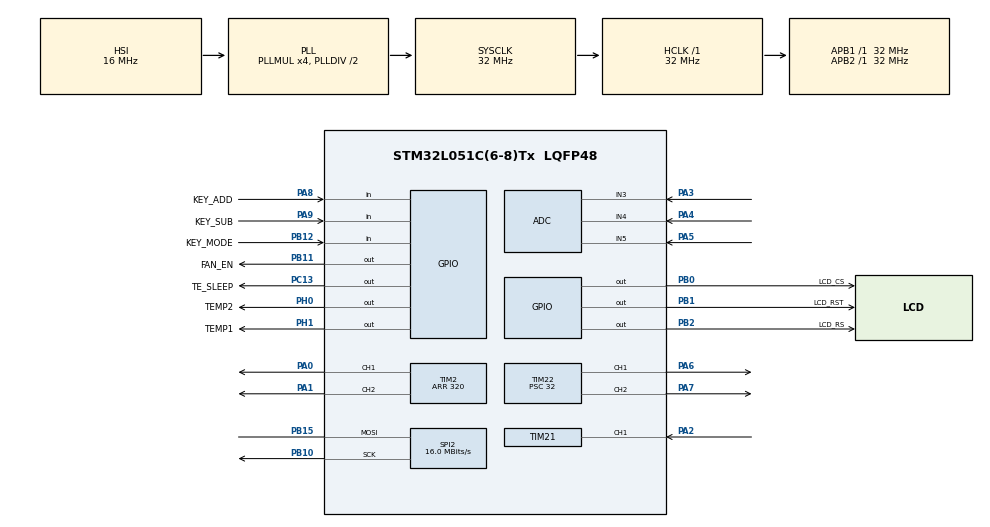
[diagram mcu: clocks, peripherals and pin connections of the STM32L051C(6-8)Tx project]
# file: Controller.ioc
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ADC.ClockPrescaler=ADC_CLOCK_ASYNC_DIV64
ADC.OversamplingMode=ENABLE
ADC.Ratio=ADC_OVERSAMPLING_RATIO_16
ADC.RightBitShift=ADC_RIGHTBITSHIFT_4
ADC.SamplingTime=ADC_SAMPLETIME_12CYCLES_5
Dma.ADC.0.Direction=DMA_PERIPH_TO_MEMORY
Dma.ADC.0.Instance=DMA1_Channel1
Dma.ADC.0.MemDataAlignment=DMA_MDATAALIGN_HALFWORD
Dma.ADC.0.MemInc=DMA_MINC_ENABLE
Dma.ADC.0.Mode=DMA_CIRCULAR
Dma.ADC.0.PeriphDataAlignment=DMA_PDATAALIGN_HALFWORD
Dma.ADC.0.PeriphInc=DMA_PINC_DISABLE
Dma.ADC.0.Priority=DMA_PRIORITY_LOW
Dma.Request0=ADC
Mcu.Family=STM32L0
Mcu.Name=STM32L051C(6-8)Tx
Mcu.Package=LQFP48
NVIC.DMA1_Channel1_IRQn=true\:2\:0\:true\:false\:true\:false\:true\:true
PA0.Signal=S_TIM2_CH1
PA1.Signal=S_TIM2_CH2
PA13.Mode=Serial_Wire
PA13.Signal=SYS_SWDIO
PA14.Mode=Serial_Wire
PA14.Signal=SYS_SWCLK
PA2.Signal=S_TIM21_CH1
PA3.Mode=IN3
PA3.Signal=ADC_IN3
PA4.Mode=IN4
PA4.Signal=ADC_IN4
PA5.Mode=IN5
PA5.Signal=ADC_IN5
PA6.Signal=S_TIM22_CH1
PA7.Signal=S_TIM22_CH2
PA8.GPIO_Label=KEY_ADD
PA8.GPIO_PuPd=GPIO_PULLUP
PA8.Signal=GPIO_Input
PA9.GPIO_Label=KEY_SUB
PA9.GPIO_PuPd=GPIO_PULLUP
PA9.Signal=GPIO_Input
PB0.GPIO_Label=LCD_CS
PB0.GPIO_Speed=GPIO_SPEED_FREQ_VERY_HIGH
PB0.Signal=GPIO_Output
PB1.GPIO_Label=LCD_RST
PB1.GPIO_Speed=GPIO_SPEED_FREQ_LOW
PB1.Signal=GPIO_Output
PB10.Mode=Simplex_Bidirectional_Master
PB10.Signal=SPI2_SCK
PB11.GPIO_Label=FAN_EN
PB11.GPIO_PuPd=GPIO_NOPULL
PB11.Signal=GPIO_Output
PB12.GPIO_Label=KEY_MODE
PB12.GPIO_PuPd=GPIO_PULLUP
PB12.Signal=GPIO_Input
PB15.Mode=Simplex_Bidirectional_Master
PB15.Signal=SPI2_MOSI
PB2.GPIO_Label=LCD_RS
PB2.GPIO_Speed=GPIO_SPEED_FREQ_VERY_HIGH
PB2.Signal=GPIO_Output
PC13.GPIO_Label=TE_SLEEP
PC13.GPIO_PuPd=GPIO_NOPULL
PC13.Signal=GPIO_Output
PH0-OSC_IN.GPIO_Label=TEMP2
PH0-OSC_IN.GPIO_ModeDefaultOutputPP=GPIO_MODE_OUTPUT_OD
PH0-OSC_IN.GPIO_PuPd=GPIO_NOPULL
PH0-OSC_IN.GPIO_Speed=GPIO_SPEED_FREQ_VERY_HIGH
PH0-OSC_IN.Signal=GPIO_Output
PH1-OSC_OUT.GPIO_Label=TEMP1
PH1-OSC_OUT.GPIO_ModeDefaultOutputPP=GPIO_MODE_OUTPUT_OD
PH1-OSC_OUT.GPIO_PuPd=GPIO_NOPULL
PH1-OSC_OUT.GPIO_Speed=GPIO_SPEED_FREQ_VERY_HIGH
PH1-OSC_OUT.Signal=GPIO_Output
ProjectManager.HeapSize=0x200
ProjectManager.StackSize=0x200
ProjectManager.TargetToolchain=STM32CubeIDE
RCC.AHBFreq_Value=32000000
RCC.APB1Freq_Value=32000000
RCC.APB1TimFreq_Value=32000000
RCC.APB2Freq_Value=32000000
RCC.APB2TimFreq_Value=32000000
RCC.HCLKFreq_Value=32000000
RCC.HSE_VALUE=8000000
RCC.HSI16_VALUE=16000000
RCC.HSI_VALUE=16000000
RCC.LSE_VALUE=32768
RCC.MSI_VALUE=2097000
RCC.PLLMUL=RCC_PLLMUL_4
RCC.SYSCLKFreq_VALUE=32000000
RCC.SYSCLKSource=RCC_SYSCLKSOURCE_PLLCLK
RCC.VCOOutputFreq_Value=64000000
SH.S_TIM21_CH1.0=TIM21_CH1,Input_Capture1_from_TI1
SH.S_TIM22_CH1.0=TIM22_CH1,PWM Generation1 CH1
SH.S_TIM22_CH2.0=TIM22_CH2,PWM Generation2 CH2
SH.S_TIM2_CH1.0=TIM2_CH1,PWM Generation1 CH1
SH.S_TIM2_CH2.0=TIM2_CH2,PWM Generation2 CH2
SPI2.BaudRatePrescaler=SPI_BAUDRATEPRESCALER_2
SPI2.CLKPolarity=SPI_POLARITY_LOW
SPI2.CalculateBaudRate=16.0 MBits/s
SPI2.Direction=SPI_DIRECTION_1LINE
SPI2.Mode=SPI_MODE_MASTER
SPI2.VirtualType=VM_MASTER
TIM2.AutoReloadPreload=TIM_AUTORELOAD_PRELOAD_ENABLE
TIM2.Channel-PWM\ Generation1\ CH1=TIM_CHANNEL_1
TIM2.Channel-PWM\ Generation2\ CH2=TIM_CHANNEL_2
TIM2.Period=320
TIM21.Channel-Input_Capture1_from_TI1=TIM_CHANNEL_1
TIM22.AutoReloadPreload=TIM_AUTORELOAD_PRELOAD_ENABLE
TIM22.Channel-PWM\ Generation1\ CH1=TIM_CHANNEL_1
TIM22.Channel-PWM\ Generation2\ CH2=TIM_CHANNEL_2
TIM22.Period=1000
TIM22.Prescaler=32
TIM6.AutoReloadPreload=TIM_AUTORELOAD_PRELOAD_ENABLE
TIM6.Period=4000
TIM6.Prescaler=32
TIM6.TIM_MasterOutputTrigger=TIM_TRGO_UPDATE
VP_ADC_TempSens_Input.Mode=IN-TempSens
VP_TIM21_VS_ClockSourceINT.Mode=Internal
VP_TIM22_VS_ClockSourceINT.Mode=Internal
VP_TIM2_VS_ClockSourceINT.Mode=Internal
VP_TIM6_VS_ClockSourceINT.Mode=Enable_Timer
board=custom

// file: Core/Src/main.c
/* USER CODE BEGIN Header */
/**
  ******************************************************************************
  * @file           : main.c
  * @brief          : Main program body
  ******************************************************************************
  * @attention
  *
  * Copyright (c) 2022 STMicroelectronics.
  * All rights reserved.
  *
  * This software is licensed under terms that can be found in the LICENSE file
  * in the root directory of this software component.
  * If no LICENSE file comes with this software, it is provided AS-IS.
  *
  ******************************************************************************
  */
/* USER CODE END Header */
#include "main.h"

/* USER CODE BEGIN Includes */

#include "userMain.hpp"

/* USER CODE END Includes */

 ADC_HandleTypeDef hadc;
DMA_HandleTypeDef hdma_adc;

SPI_HandleTypeDef hspi2;

TIM_HandleTypeDef htim2;
TIM_HandleTypeDef htim6;
TIM_HandleTypeDef htim21;
TIM_HandleTypeDef htim22;

void SystemClock_Config(void);
static void MX_GPIO_Init(void);
static void MX_ADC_Init(void);
static void MX_SPI2_Init(void);
static void MX_TIM2_Init(void);
static void MX_DMA_Init(void);
static void MX_TIM22_Init(void);
static void MX_TIM21_Init(void);
static void MX_TIM6_Init(void);

int main(void)
{

  /* MCU Configuration--------------------------------------------------------*/

  /* Reset of all peripherals, Initializes the Flash interface and the Systick. */
  HAL_Init();

  /* Configure the system clock */
  SystemClock_Config();

  /* Initialize all configured peripherals */
  MX_GPIO_Init();
  MX_ADC_Init();
  MX_SPI2_Init();
  MX_TIM2_Init();
  MX_DMA_Init();
  MX_TIM22_Init();
  MX_TIM21_Init();
  MX_TIM6_Init();
  /* USER CODE BEGIN 2 */
  userMain();
  /* USER CODE END 2 */

  /* Infinite loop */
  while (1)
  {

  }
}

void SystemClock_Config(void)
{
  RCC_OscInitTypeDef RCC_OscInitStruct = {0};
  RCC_ClkInitTypeDef RCC_ClkInitStruct = {0};

  /** Configure the main internal regulator output voltage
  */
  __HAL_PWR_VOLTAGESCALING_CONFIG(PWR_REGULATOR_VOLTAGE_SCALE1);

  /** Initializes the RCC Oscillators according to the specified parameters
  * in the RCC_OscInitTypeDef structure.
  */
  RCC_OscInitStruct.OscillatorType = RCC_OSCILLATORTYPE_HSI;
  RCC_OscInitStruct.HSIState = RCC_HSI_ON;
  RCC_OscInitStruct.HSICalibrationValue = RCC_HSICALIBRATION_DEFAULT;
  RCC_OscInitStruct.PLL.PLLState = RCC_PLL_ON;
  RCC_OscInitStruct.PLL.PLLSource = RCC_PLLSOURCE_HSI;
  RCC_OscInitStruct.PLL.PLLMUL = RCC_PLLMUL_4;
  RCC_OscInitStruct.PLL.PLLDIV = RCC_PLLDIV_2;
  if (HAL_RCC_OscConfig(&RCC_OscInitStruct) != HAL_OK)
  {
    Error_Handler();
  }

  /** Initializes the CPU, AHB and APB buses clocks
  */
  RCC_ClkInitStruct.ClockType = RCC_CLOCKTYPE_HCLK|RCC_CLOCKTYPE_SYSCLK
                              |RCC_CLOCKTYPE_PCLK1|RCC_CLOCKTYPE_PCLK2;
  RCC_ClkInitStruct.SYSCLKSource = RCC_SYSCLKSOURCE_PLLCLK;
  RCC_ClkInitStruct.AHBCLKDivider = RCC_SYSCLK_DIV1;
  RCC_ClkInitStruct.APB1CLKDivider = RCC_HCLK_DIV1;
  RCC_ClkInitStruct.APB2CLKDivider = RCC_HCLK_DIV1;

  if (HAL_RCC_ClockConfig(&RCC_ClkInitStruct, FLASH_LATENCY_1) != HAL_OK)
  {
    Error_Handler();
  }
  HAL_RCC_MCOConfig(RCC_MCO1, RCC_MCO1SOURCE_SYSCLK, RCC_MCODIV_1);
}

static void MX_ADC_Init(void)
{

  ADC_ChannelConfTypeDef sConfig = {0};

  /** Configure the global features of the ADC (Clock, Resolution, Data Alignment and number of conversion)
  */
  hadc.Instance = ADC1;
  hadc.Init.OversamplingMode = ENABLE;
  hadc.Init.Oversample.Ratio = ADC_OVERSAMPLING_RATIO_16;
  hadc.Init.Oversample.RightBitShift = ADC_RIGHTBITSHIFT_4;
  hadc.Init.Oversample.TriggeredMode = ADC_TRIGGEREDMODE_SINGLE_TRIGGER;
  hadc.Init.ClockPrescaler = ADC_CLOCK_ASYNC_DIV64;
  hadc.Init.Resolution = ADC_RESOLUTION_12B;
  hadc.Init.SamplingTime = ADC_SAMPLETIME_12CYCLES_5;
  hadc.Init.ScanConvMode = ADC_SCAN_DIRECTION_FORWARD;
  hadc.Init.DataAlign = ADC_DATAALIGN_RIGHT;
  hadc.Init.ContinuousConvMode = DISABLE;
  hadc.Init.DiscontinuousConvMode = DISABLE;
  hadc.Init.ExternalTrigConvEdge = ADC_EXTERNALTRIGCONVEDGE_NONE;
  hadc.Init.ExternalTrigConv = ADC_SOFTWARE_START;
  hadc.Init.DMAContinuousRequests = DISABLE;
  hadc.Init.EOCSelection = ADC_EOC_SINGLE_CONV;
  hadc.Init.Overrun = ADC_OVR_DATA_PRESERVED;
  hadc.Init.LowPowerAutoWait = DISABLE;
  hadc.Init.LowPowerFrequencyMode = ENABLE;
  hadc.Init.LowPowerAutoPowerOff = DISABLE;
  if (HAL_ADC_Init(&hadc) != HAL_OK)
  {
    Error_Handler();
  }

  /** Configure for the selected ADC regular channel to be converted.
  */
  sConfig.Channel = ADC_CHANNEL_3;
  sConfig.Rank = ADC_RANK_CHANNEL_NUMBER;
  if (HAL_ADC_ConfigChannel(&hadc, &sConfig) != HAL_OK)
  {
    Error_Handler();
  }

  /** Configure for the selected ADC regular channel to be converted.
  */
  sConfig.Channel = ADC_CHANNEL_4;
  if (HAL_ADC_ConfigChannel(&hadc, &sConfig) != HAL_OK)
  {
    Error_Handler();
  }

  /** Configure for the selected ADC regular channel to be converted.
  */
  sConfig.Channel = ADC_CHANNEL_5;
  if (HAL_ADC_ConfigChannel(&hadc, &sConfig) != HAL_OK)
  {
    Error_Handler();
  }

  /** Configure for the selected ADC regular channel to be converted.
  */
  sConfig.Channel = ADC_CHANNEL_TEMPSENSOR;
  if (HAL_ADC_ConfigChannel(&hadc, &sConfig) != HAL_OK)
  {
    Error_Handler();
  }

}

static void MX_SPI2_Init(void)
{

  /* SPI2 parameter configuration*/
  hspi2.Instance = SPI2;
  hspi2.Init.Mode = SPI_MODE_MASTER;
  hspi2.Init.Direction = SPI_DIRECTION_1LINE;
  hspi2.Init.DataSize = SPI_DATASIZE_8BIT;
  hspi2.Init.CLKPolarity = SPI_POLARITY_LOW;
  hspi2.Init.CLKPhase = SPI_PHASE_1EDGE;
  hspi2.Init.NSS = SPI_NSS_SOFT;
  hspi2.Init.BaudRatePrescaler = SPI_BAUDRATEPRESCALER_2;
  hspi2.Init.FirstBit = SPI_FIRSTBIT_MSB;
  hspi2.Init.TIMode = SPI_TIMODE_DISABLE;
  hspi2.Init.CRCCalculation = SPI_CRCCALCULATION_DISABLE;
  hspi2.Init.CRCPolynomial = 7;
  if (HAL_SPI_Init(&hspi2) != HAL_OK)
  {
    Error_Handler();
  }

}

static void MX_TIM2_Init(void)
{

  TIM_ClockConfigTypeDef sClockSourceConfig = {0};
  TIM_MasterConfigTypeDef sMasterConfig = {0};
  TIM_OC_InitTypeDef sConfigOC = {0};

  htim2.Instance = TIM2;
  htim2.Init.Prescaler = 0;
  htim2.Init.CounterMode = TIM_COUNTERMODE_UP;
  htim2.Init.Period = 320;
  htim2.Init.ClockDivision = TIM_CLOCKDIVISION_DIV1;
  htim2.Init.AutoReloadPreload = TIM_AUTORELOAD_PRELOAD_ENABLE;
  if (HAL_TIM_Base_Init(&htim2) != HAL_OK)
  {
    Error_Handler();
  }
  sClockSourceConfig.ClockSource = TIM_CLOCKSOURCE_INTERNAL;
  if (HAL_TIM_ConfigClockSource(&htim2, &sClockSourceConfig) != HAL_OK)
  {
    Error_Handler();
  }
  if (HAL_TIM_PWM_Init(&htim2) != HAL_OK)
  {
    Error_Handler();
  }
  sMasterConfig.MasterOutputTrigger = TIM_TRGO_RESET;
  sMasterConfig.MasterSlaveMode = TIM_MASTERSLAVEMODE_DISABLE;
  if (HAL_TIMEx_MasterConfigSynchronization(&htim2, &sMasterConfig) != HAL_OK)
  {
    Error_Handler();
  }
  sConfigOC.OCMode = TIM_OCMODE_PWM1;
  sConfigOC.Pulse = 0;
  sConfigOC.OCPolarity = TIM_OCPOLARITY_HIGH;
  sConfigOC.OCFastMode = TIM_OCFAST_DISABLE;
  if (HAL_TIM_PWM_ConfigChannel(&htim2, &sConfigOC, TIM_CHANNEL_1) != HAL_OK)
  {
    Error_Handler();
  }
  if (HAL_TIM_PWM_ConfigChannel(&htim2, &sConfigOC, TIM_CHANNEL_2) != HAL_OK)
  {
    Error_Handler();
  }
  HAL_TIM_MspPostInit(&htim2);

}

static void MX_TIM6_Init(void)
{

  TIM_MasterConfigTypeDef sMasterConfig = {0};

  htim6.Instance = TIM6;
  htim6.Init.Prescaler = 32;
  htim6.Init.CounterMode = TIM_COUNTERMODE_UP;
  htim6.Init.Period = 4000;
  htim6.Init.AutoReloadPreload = TIM_AUTORELOAD_PRELOAD_ENABLE;
  if (HAL_TIM_Base_Init(&htim6) != HAL_OK)
  {
    Error_Handler();
  }
  sMasterConfig.MasterOutputTrigger = TIM_TRGO_UPDATE;
  sMasterConfig.MasterSlaveMode = TIM_MASTERSLAVEMODE_DISABLE;
  if (HAL_TIMEx_MasterConfigSynchronization(&htim6, &sMasterConfig) != HAL_OK)
  {
    Error_Handler();
  }
  /* USER CODE BEGIN TIM6_Init 2 */
  HAL_NVIC_SetPriority(TIM6_DAC_IRQn, 3 ,0);
  HAL_NVIC_EnableIRQ(TIM6_DAC_IRQn);
  /* USER CODE END TIM6_Init 2 */

}

static void MX_TIM21_Init(void)
{

  TIM_ClockConfigTypeDef sClockSourceConfig = {0};
  TIM_MasterConfigTypeDef sMasterConfig = {0};
  TIM_IC_InitTypeDef sConfigIC = {0};

  htim21.Instance = TIM21;
  htim21.Init.Prescaler = 0;
  htim21.Init.CounterMode = TIM_COUNTERMODE_UP;
  htim21.Init.Period = 65535;
  htim21.Init.ClockDivision = TIM_CLOCKDIVISION_DIV1;
  htim21.Init.AutoReloadPreload = TIM_AUTORELOAD_PRELOAD_DISABLE;
  if (HAL_TIM_Base_Init(&htim21) != HAL_OK)
  {
    Error_Handler();
  }
  sClockSourceConfig.ClockSource = TIM_CLOCKSOURCE_INTERNAL;
  if (HAL_TIM_ConfigClockSource(&htim21, &sClockSourceConfig) != HAL_OK)
  {
    Error_Handler();
  }
  if (HAL_TIM_IC_Init(&htim21) != HAL_OK)
  {
    Error_Handler();
  }
  sMasterConfig.MasterOutputTrigger = TIM_TRGO_RESET;
  sMasterConfig.MasterSlaveMode = TIM_MASTERSLAVEMODE_DISABLE;
  if (HAL_TIMEx_MasterConfigSynchronization(&htim21, &sMasterConfig) != HAL_OK)
  {
    Error_Handler();
  }
  sConfigIC.ICPolarity = TIM_INPUTCHANNELPOLARITY_RISING;
  sConfigIC.ICSelection = TIM_ICSELECTION_DIRECTTI;
  sConfigIC.ICPrescaler = TIM_ICPSC_DIV1;
  sConfigIC.ICFilter = 0;
  if (HAL_TIM_IC_ConfigChannel(&htim21, &sConfigIC, TIM_CHANNEL_1) != HAL_OK)
  {
    Error_Handler();
  }

}

static void MX_TIM22_Init(void)
{

  TIM_ClockConfigTypeDef sClockSourceConfig = {0};
  TIM_MasterConfigTypeDef sMasterConfig = {0};
  TIM_OC_InitTypeDef sConfigOC = {0};

  htim22.Instance = TIM22;
  htim22.Init.Prescaler = 32;
  htim22.Init.CounterMode = TIM_COUNTERMODE_UP;
  htim22.Init.Period = 1000;
  htim22.Init.ClockDivision = TIM_CLOCKDIVISION_DIV1;
  htim22.Init.AutoReloadPreload = TIM_AUTORELOAD_PRELOAD_ENABLE;
  if (HAL_TIM_Base_Init(&htim22) != HAL_OK)
  {
    Error_Handler();
  }
  sClockSourceConfig.ClockSource = TIM_CLOCKSOURCE_INTERNAL;
  if (HAL_TIM_ConfigClockSource(&htim22, &sClockSourceConfig) != HAL_OK)
  {
    Error_Handler();
  }
  if (HAL_TIM_PWM_Init(&htim22) != HAL_OK)
  {
    Error_Handler();
  }
  sMasterConfig.MasterOutputTrigger = TIM_TRGO_RESET;
  sMasterConfig.MasterSlaveMode = TIM_MASTERSLAVEMODE_DISABLE;
  if (HAL_TIMEx_MasterConfigSynchronization(&htim22, &sMasterConfig) != HAL_OK)
  {
    Error_Handler();
  }
  sConfigOC.OCMode = TIM_OCMODE_PWM1;
  sConfigOC.Pulse = 0;
  sConfigOC.OCPolarity = TIM_OCPOLARITY_HIGH;
  sConfigOC.OCFastMode = TIM_OCFAST_DISABLE;
  if (HAL_TIM_PWM_ConfigChannel(&htim22, &sConfigOC, TIM_CHANNEL_1) != HAL_OK)
  {
    Error_Handler();
  }
  if (HAL_TIM_PWM_ConfigChannel(&htim22, &sConfigOC, TIM_CHANNEL_2) != HAL_OK)
  {
    Error_Handler();
  }
  HAL_TIM_MspPostInit(&htim22);

}

static void MX_DMA_Init(void)
{

  /* DMA controller clock enable */
  __HAL_RCC_DMA1_CLK_ENABLE();

  /* DMA interrupt init */
  /* DMA1_Channel1_IRQn interrupt configuration */
  HAL_NVIC_SetPriority(DMA1_Channel1_IRQn, 2, 0);
  HAL_NVIC_EnableIRQ(DMA1_Channel1_IRQn);

}

static void MX_GPIO_Init(void)
{
  GPIO_InitTypeDef GPIO_InitStruct = {0};

  /* GPIO Ports Clock Enable */
  __HAL_RCC_GPIOC_CLK_ENABLE();
  __HAL_RCC_GPIOH_CLK_ENABLE();
  __HAL_RCC_GPIOA_CLK_ENABLE();
  __HAL_RCC_GPIOB_CLK_ENABLE();

  /*Configure GPIO pin Output Level */
  HAL_GPIO_WritePin(TE_SLEEP_GPIO_Port, TE_SLEEP_Pin, GPIO_PIN_RESET);

  /*Configure GPIO pin Output Level */
  HAL_GPIO_WritePin(GPIOH, TEMP2_Pin|TEMP1_Pin, GPIO_PIN_RESET);

  /*Configure GPIO pin Output Level */
  HAL_GPIO_WritePin(GPIOB, LCD_CS_Pin|LCD_RST_Pin|LCD_RS_Pin|FAN_EN_Pin, GPIO_PIN_RESET);

  /*Configure GPIO pin : TE_SLEEP_Pin */
  GPIO_InitStruct.Pin = TE_SLEEP_Pin;
  GPIO_InitStruct.Mode = GPIO_MODE_OUTPUT_PP;
  GPIO_InitStruct.Pull = GPIO_NOPULL;
  GPIO_InitStruct.Speed = GPIO_SPEED_FREQ_LOW;
  HAL_GPIO_Init(TE_SLEEP_GPIO_Port, &GPIO_InitStruct);

  /*Configure GPIO pins : TEMP2_Pin TEMP1_Pin */
  GPIO_InitStruct.Pin = TEMP2_Pin|TEMP1_Pin;
  GPIO_InitStruct.Mode = GPIO_MODE_OUTPUT_OD;
  GPIO_InitStruct.Pull = GPIO_NOPULL;
  GPIO_InitStruct.Speed = GPIO_SPEED_FREQ_VERY_HIGH;
  HAL_GPIO_Init(GPIOH, &GPIO_InitStruct);

  /*Configure GPIO pins : LCD_CS_Pin LCD_RS_Pin */
  GPIO_InitStruct.Pin = LCD_CS_Pin|LCD_RS_Pin;
  GPIO_InitStruct.Mode = GPIO_MODE_OUTPUT_PP;
  GPIO_InitStruct.Pull = GPIO_NOPULL;
  GPIO_InitStruct.Speed = GPIO_SPEED_FREQ_VERY_HIGH;
  HAL_GPIO_Init(GPIOB, &GPIO_InitStruct);

  /*Configure GPIO pins : LCD_RST_Pin FAN_EN_Pin */
  GPIO_InitStruct.Pin = LCD_RST_Pin|FAN_EN_Pin;
  GPIO_InitStruct.Mode = GPIO_MODE_OUTPUT_PP;
  GPIO_InitStruct.Pull = GPIO_NOPULL;
  GPIO_InitStruct.Speed = GPIO_SPEED_FREQ_LOW;
  HAL_GPIO_Init(GPIOB, &GPIO_InitStruct);

  /*Configure GPIO pin : KEY_MODE_Pin */
  GPIO_InitStruct.Pin = KEY_MODE_Pin;
  GPIO_InitStruct.Mode = GPIO_MODE_INPUT;
  GPIO_InitStruct.Pull = GPIO_PULLUP;
  HAL_GPIO_Init(KEY_MODE_GPIO_Port, &GPIO_InitStruct);

  /*Configure GPIO pins : KEY_ADD_Pin KEY_SUB_Pin */
  GPIO_InitStruct.Pin = KEY_ADD_Pin|KEY_SUB_Pin;
  GPIO_InitStruct.Mode = GPIO_MODE_INPUT;
  GPIO_InitStruct.Pull = GPIO_PULLUP;
  HAL_GPIO_Init(GPIOA, &GPIO_InitStruct);

}

void Error_Handler(void)
{
  __disable_irq();
  while (1)
  {
  }
}
